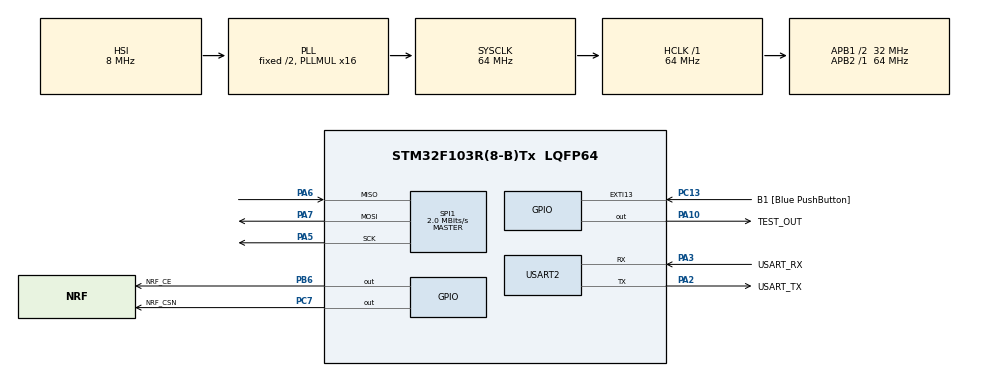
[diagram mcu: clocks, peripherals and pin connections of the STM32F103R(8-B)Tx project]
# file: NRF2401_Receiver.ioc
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Mcu.Family=STM32F1
Mcu.Name=STM32F103R(8-B)Tx
Mcu.Package=LQFP64
NVIC.EXTI15_10_IRQn=true\:0\:0\:false\:false\:true\:true\:true\:true
NVIC.PriorityGroup=NVIC_PRIORITYGROUP_4
NVIC.TIM1_UP_IRQn=true\:0\:0\:false\:true\:true\:1\:true\:true\:true
PA10.GPIO_Label=TEST_OUT
PA10.GPIO_Speed=GPIO_SPEED_FREQ_HIGH
PA10.Signal=GPIO_Output
PA13.GPIO_Label=TMS
PA13.Mode=Serial_Wire
PA13.Signal=SYS_JTMS-SWDIO
PA14.GPIO_Label=TCK
PA14.Mode=Serial_Wire
PA14.Signal=SYS_JTCK-SWCLK
PA2.GPIO_Label=USART_TX
PA2.GPIO_Mode=GPIO_MODE_AF_PP
PA2.GPIO_PuPd=GPIO_NOPULL
PA2.GPIO_Speed=GPIO_SPEED_FREQ_LOW
PA2.Mode=Asynchronous
PA2.Signal=USART2_TX
PA3.GPIO_Label=USART_RX
PA3.GPIO_Mode=GPIO_MODE_AF_PP
PA3.GPIO_PuPd=GPIO_NOPULL
PA3.GPIO_Speed=GPIO_SPEED_FREQ_LOW
PA3.Mode=Asynchronous
PA3.Signal=USART2_RX
PA5.Mode=Full_Duplex_Master
PA5.Signal=SPI1_SCK
PA6.Mode=Full_Duplex_Master
PA6.Signal=SPI1_MISO
PA7.Mode=Full_Duplex_Master
PA7.Signal=SPI1_MOSI
PB3.GPIO_Label=SWO
PB3.Signal=SYS_JTDO-TRACESWO
PB6.GPIO_Label=NRF_CE
PB6.GPIO_Speed=GPIO_SPEED_FREQ_HIGH
PB6.Signal=GPIO_Output
PC13-TAMPER-RTC.GPIO_Label=B1 [Blue PushButton]
PC13-TAMPER-RTC.GPIO_PuPd=GPIO_NOPULL
PC13-TAMPER-RTC.Signal=GPXTI13
PC14-OSC32_IN.Mode=LSE-External-Oscillator
PC14-OSC32_IN.Signal=RCC_OSC32_IN
PC15-OSC32_OUT.Mode=LSE-External-Oscillator
PC15-OSC32_OUT.Signal=RCC_OSC32_OUT
PC7.GPIO_Label=NRF_CSN
PC7.GPIO_Speed=GPIO_SPEED_FREQ_HIGH
PC7.Signal=GPIO_Output
PD0-OSC_IN.Mode=HSE-External-Clock-Source
PD0-OSC_IN.Signal=RCC_OSC_IN
PD1-OSC_OUT.Mode=HSE-External-Clock-Source
PD1-OSC_OUT.Signal=RCC_OSC_OUT
ProjectManager.HeapSize=0x200
ProjectManager.StackSize=0x400
ProjectManager.TargetToolchain=STM32CubeIDE
RCC.AHBFreq_Value=64000000
RCC.APB1CLKDivider=RCC_HCLK_DIV2
RCC.APB1Freq_Value=32000000
RCC.APB1TimFreq_Value=64000000
RCC.APB2Freq_Value=64000000
RCC.APB2TimFreq_Value=64000000
RCC.HCLKFreq_Value=64000000
RCC.PLLMUL=RCC_PLL_MUL16
RCC.RTCClockSelection=RCC_RTCCLKSOURCE_LSE
RCC.SYSCLKFreq_VALUE=64000000
RCC.SYSCLKSource=RCC_SYSCLKSOURCE_PLLCLK
RCC.USBFreq_Value=64000000
SPI1.BaudRatePrescaler=SPI_BAUDRATEPRESCALER_32
SPI1.CalculateBaudRate=2.0 MBits/s
SPI1.Direction=SPI_DIRECTION_2LINES
SPI1.Mode=SPI_MODE_MASTER
SPI1.VirtualType=VM_MASTER
TIM1.Period=9
TIM1.Prescaler=639
USART2.VirtualMode=VM_ASYNC
VP_TIM1_VS_ClockSourceINT.Mode=Internal
board=NUCLEO-F103RB

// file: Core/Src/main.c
/* USER CODE BEGIN Header */
/**
  ******************************************************************************
  * @file           : main.c
  * @brief          : Main program body
  ******************************************************************************
  * @attention
  *
  * Copyright (c) 2022 STMicroelectronics.
  * All rights reserved.
  *
  * This software is licensed under terms that can be found in the LICENSE file
  * in the root directory of this software component.
  * If no LICENSE file comes with this software, it is provided AS-IS.
  *
  ******************************************************************************
  */
/* USER CODE END Header */

#include "main.h"
#include "spi.h"
#include "tim.h"
#include "usart.h"
#include "gpio.h"

/* USER CODE BEGIN Includes */
#include "NRF2401/nrf2401.h"
#include "NRF2401/nrf2401_defs.h"
#include "clock.h"
#include "stdio.h"
/* USER CODE END Includes */

void SystemClock_Config(void);
static void MX_NVIC_Init(void);
/* USER CODE BEGIN PFP */
int __io_putchar(int ch)
{
    if (ch == '\n') {
        uint8_t ch2 = '\r';
        HAL_UART_Transmit(&huart2, &ch2, 1, 1000);
    }

    HAL_UART_Transmit(&huart2, (uint8_t*)&ch, 1, 1000);
    return 1;
}
/* USER CODE END PFP */

int main(void)
{

  /* MCU Configuration--------------------------------------------------------*/

  /* Reset of all peripherals, Initializes the Flash interface and the Systick. */
  HAL_Init();

  /* Configure the system clock */
  SystemClock_Config();

  /* Initialize all configured peripherals */
  MX_GPIO_Init();
  MX_USART2_UART_Init();
  MX_SPI1_Init();
  MX_TIM1_Init();

  /* Initialize interrupts */
  MX_NVIC_Init();
  /* USER CODE BEGIN 2 */
  Clock_Init(&htim1);
  NRF_Init(&hspi1, 'r');
  /* USER CODE END 2 */

  /* Infinite loop */
  /* USER CODE BEGIN WHILE */
  while (1)
  {
	  NRF_process(0);
    /* USER CODE END WHILE */

  }
}

void SystemClock_Config(void)
{
  RCC_OscInitTypeDef RCC_OscInitStruct = {0};
  RCC_ClkInitTypeDef RCC_ClkInitStruct = {0};

  /** Initializes the RCC Oscillators according to the specified parameters
  * in the RCC_OscInitTypeDef structure.
  */
  RCC_OscInitStruct.OscillatorType = RCC_OSCILLATORTYPE_HSI;
  RCC_OscInitStruct.HSIState = RCC_HSI_ON;
  RCC_OscInitStruct.HSICalibrationValue = RCC_HSICALIBRATION_DEFAULT;
  RCC_OscInitStruct.PLL.PLLState = RCC_PLL_ON;
  RCC_OscInitStruct.PLL.PLLSource = RCC_PLLSOURCE_HSI_DIV2;
  RCC_OscInitStruct.PLL.PLLMUL = RCC_PLL_MUL16;
  if (HAL_RCC_OscConfig(&RCC_OscInitStruct) != HAL_OK)
  {
    Error_Handler();
  }

  /** Initializes the CPU, AHB and APB buses clocks
  */
  RCC_ClkInitStruct.ClockType = RCC_CLOCKTYPE_HCLK|RCC_CLOCKTYPE_SYSCLK
                              |RCC_CLOCKTYPE_PCLK1|RCC_CLOCKTYPE_PCLK2;
  RCC_ClkInitStruct.SYSCLKSource = RCC_SYSCLKSOURCE_PLLCLK;
  RCC_ClkInitStruct.AHBCLKDivider = RCC_SYSCLK_DIV1;
  RCC_ClkInitStruct.APB1CLKDivider = RCC_HCLK_DIV2;
  RCC_ClkInitStruct.APB2CLKDivider = RCC_HCLK_DIV1;

  if (HAL_RCC_ClockConfig(&RCC_ClkInitStruct, FLASH_LATENCY_2) != HAL_OK)
  {
    Error_Handler();
  }
}

/**
  * @brief NVIC Configuration.
  * @retval None
  */
static void MX_NVIC_Init(void)
{
  /* TIM1_UP_IRQn interrupt configuration */
  HAL_NVIC_SetPriority(TIM1_UP_IRQn, 0, 0);
  HAL_NVIC_EnableIRQ(TIM1_UP_IRQn);
}

void Error_Handler(void)
{
  __disable_irq();
  while (1)
  {
  }
}
